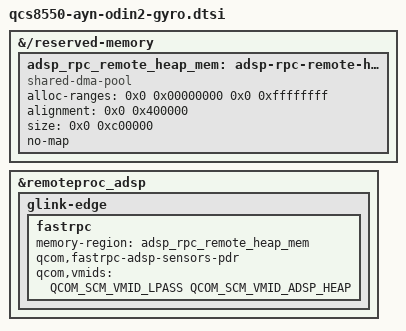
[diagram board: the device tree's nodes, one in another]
// SPDX-License-Identifier: BSD-3-Clause
/*
 * Gyro for the AYN Odin 2 / Mini / Portal (included from their dts appends,
 * not from qcs8550-ayn-common.dtsi). The Thor includes it from
 * qcs8550-ayn-thor-gyro.dtsi and adds its pd-type banks there.
 *
 * The IMU hangs off the ADSP's Sensor Core. hexagonrpcd starts the sensors
 * PD, which needs a remote heap handed to the ADSP and PDR for the sensors
 * service (patch 0052). No qcom,pd-type here: on the Odin 2 it kept the
 * sensors service from showing up.
 */
#include <dt-bindings/firmware/qcom,scm.h>

&{/reserved-memory} {
	adsp_rpc_remote_heap_mem: adsp-rpc-remote-heap {
		compatible = "shared-dma-pool";
		alloc-ranges = <0x0 0x00000000 0x0 0xffffffff>;
		alignment = <0x0 0x400000>;
		size = <0x0 0xc00000>;
		/*
		 * no-map, not reusable: from Linux 7.3.4 / 7.4 fastrpc hands the
		 * whole region to the ADSP at probe. A reusable (CMA) pool keeps
		 * lending those pages to Linux, and the board resets under memory
		 * pressure (issue 102).
		 */
		no-map;
	};
};

&remoteproc_adsp {
	glink-edge {
		fastrpc {
			memory-region = <&adsp_rpc_remote_heap_mem>;
			qcom,fastrpc-adsp-sensors-pdr;
			qcom,vmids = <QCOM_SCM_VMID_LPASS QCOM_SCM_VMID_ADSP_HEAP>;
		};
	};
};
